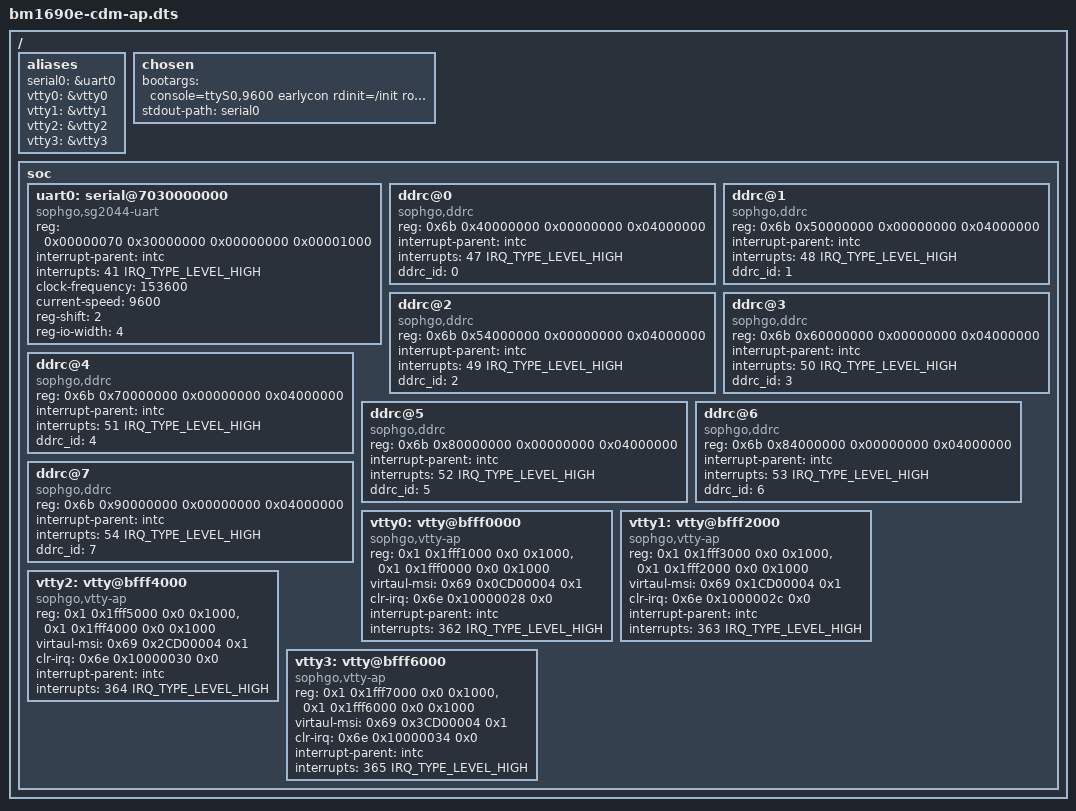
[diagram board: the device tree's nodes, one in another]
// SPDX-License-Identifier: (GPL-2.0 OR MIT)
/*
 * Copyright (C) 2022 Sophgo Technology Inc. All rights reserved.
 */

/dts-v1/;
#include <dt-bindings/interrupt-controller/irq.h>
#include "bm1690-cpu-ap.dtsi"

/ {
	aliases {
		serial0 = &uart0;
		vtty0 = &vtty0;
		vtty1 = &vtty1;
		vtty2 = &vtty2;
		vtty3 = &vtty3;
	};

	chosen {
		bootargs = "console=ttyS0,9600 earlycon rdinit=/init root=/dev/ram0 rw initrd=0x8b000000,32M maxcpus=4";
		stdout-path = "serial0";
	};

	soc {
		uart0: serial@7030000000 {
			compatible = "sophgo,sg2044-uart", "snps,dw-apb-uart";
			reg = <0x00000070 0x30000000 0x00000000 0x00001000>;
			interrupt-parent = <&intc>;
			interrupts = <41 IRQ_TYPE_LEVEL_HIGH>;
			clock-frequency = <153600>;
			current-speed = <9600>;
			reg-shift = <2>;
			reg-io-width = <4>;
		};

		ddrc@0 {
			compatible = "sophgo,ddrc";

			reg = <0x6b 0x40000000 0x00000000 0x04000000>;
			interrupt-parent = <&intc>;
			interrupts = <47 IRQ_TYPE_LEVEL_HIGH>;
			// trigger_error_index = <0x0201060c>;
			ddrc_id = <0>;
		};
		ddrc@1 {
			compatible = "sophgo,ddrc";

			reg = <0x6b 0x50000000 0x00000000 0x04000000>;
			interrupt-parent = <&intc>;
			interrupts = <48 IRQ_TYPE_LEVEL_HIGH>;
			// trigger_error_index = <0x0201060c>;
			ddrc_id = <1>;
		};
		ddrc@2 {
			compatible = "sophgo,ddrc";

			reg = <0x6b 0x54000000 0x00000000 0x04000000>;
			interrupt-parent = <&intc>;
			interrupts = <49 IRQ_TYPE_LEVEL_HIGH>;
			// trigger_error_index = <0x0201060c>;
			ddrc_id = <2>;
		};
		ddrc@3 {
			compatible = "sophgo,ddrc";

			reg = <0x6b 0x60000000 0x00000000 0x04000000>;
			interrupt-parent = <&intc>;
			interrupts = <50 IRQ_TYPE_LEVEL_HIGH>;
			// trigger_error_index = <0x0201060c>;
			ddrc_id = <3>;
		};
		ddrc@4 {
			compatible = "sophgo,ddrc";

			reg = <0x6b 0x70000000 0x00000000 0x04000000>;
			interrupt-parent = <&intc>;
			interrupts = <51 IRQ_TYPE_LEVEL_HIGH>;
			// trigger_error_index = <0x0201060c>;
			ddrc_id = <4>;
		};
		ddrc@5 {
			compatible = "sophgo,ddrc";

			reg = <0x6b 0x80000000 0x00000000 0x04000000>;
			interrupt-parent = <&intc>;
			interrupts = <52 IRQ_TYPE_LEVEL_HIGH>;
			// trigger_error_index = <0x0201060c>;
			ddrc_id = <5>;
		};
		ddrc@6 {
			compatible = "sophgo,ddrc";

			reg = <0x6b 0x84000000 0x00000000 0x04000000>;
			interrupt-parent = <&intc>;
			interrupts = <53 IRQ_TYPE_LEVEL_HIGH>;
			// trigger_error_index = <0x0201060c>;
			ddrc_id = <6>;
		};
		ddrc@7 {
			compatible = "sophgo,ddrc";

			reg = <0x6b 0x90000000 0x00000000 0x04000000>;
			interrupt-parent = <&intc>;
			interrupts = <54 IRQ_TYPE_LEVEL_HIGH>;
			// trigger_error_index = <0x0201060c>;
			ddrc_id = <7>;
		};

		vtty0: vtty@bfff0000 {
			compatible = "sophgo,vtty-ap";
			#size-cells = <0x2>;
			#address-cells = <0x2>;
			reg = <0x1 0x1fff1000 0x0 0x1000>,
				<0x1 0x1fff0000 0x0 0x1000>;
			virtaul-msi = <0x69 0x0CD00004 0x1>;
			clr-irq = <0x6e 0x10000028 0x0>;
			interrupt-parent = <&intc>;
			interrupts = <362 IRQ_TYPE_LEVEL_HIGH>;
		};

		vtty1: vtty@bfff2000 {
			compatible = "sophgo,vtty-ap";
			#size-cells = <0x2>;
			#address-cells = <0x2>;
			reg = <0x1 0x1fff3000 0x0 0x1000>,
				<0x1 0x1fff2000 0x0 0x1000>;
			virtaul-msi = <0x69 0x1CD00004 0x1>;
			clr-irq = <0x6e 0x1000002c 0x0>;
			interrupt-parent = <&intc>;
			interrupts = <363 IRQ_TYPE_LEVEL_HIGH>;
		};

		vtty2: vtty@bfff4000 {
			compatible = "sophgo,vtty-ap";
			#size-cells = <0x2>;
			#address-cells = <0x2>;
			reg = <0x1 0x1fff5000 0x0 0x1000>,
				<0x1 0x1fff4000 0x0 0x1000>;
			virtaul-msi = <0x69 0x2CD00004 0x1>;
			clr-irq = <0x6e 0x10000030 0x0>;
			interrupt-parent = <&intc>;
			interrupts = <364 IRQ_TYPE_LEVEL_HIGH>;
		};

		vtty3: vtty@bfff6000 {
			compatible = "sophgo,vtty-ap";
			#size-cells = <0x2>;
			#address-cells = <0x2>;
			reg = <0x1 0x1fff7000 0x0 0x1000>,
				<0x1 0x1fff6000 0x0 0x1000>;
			virtaul-msi = <0x69 0x3CD00004 0x1>;
			clr-irq = <0x6e 0x10000034 0x0>;
			interrupt-parent = <&intc>;
			interrupts = <365 IRQ_TYPE_LEVEL_HIGH>;
		};

	};
};
